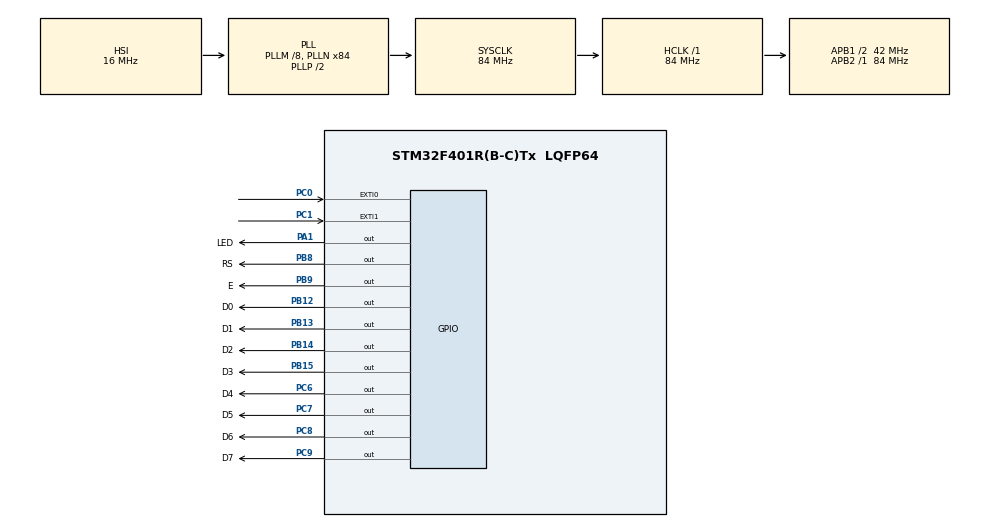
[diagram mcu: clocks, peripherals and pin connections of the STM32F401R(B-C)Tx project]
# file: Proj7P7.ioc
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Mcu.Family=STM32F4
RCC.CortexFreq_Value=84000000
PB9.GPIO_Label=E
PC9.GPIO_Label=D7
PB14.GPIO_Label=D2
PC8.Signal=GPIO_Output
PC6.Signal=GPIO_Output
PC6.GPIO_Label=D4
PC0.Signal=GPXTI0
RCC.APB1CLKDivider=RCC_HCLK_DIV2
PB13.GPIO_Label=D1
PB13.Signal=GPIO_Output
PB15.Signal=GPIO_Output
RCC.SYSCLKSource=RCC_SYSCLKSOURCE_PLLCLK
ProjectManager.StackSize=0x400
PC8.GPIO_Label=D6
PB8.GPIO_Label=RS
NVIC.EXTI1_IRQn=true\:0\:0\:false\:false\:true\:true\:true
TIM1.Prescaler=0
ProjectManager.TargetToolchain=STM32CubeIDE
RCC.HCLKFreq_Value=84000000
RCC.APB2TimFreq_Value=84000000
PC7.Signal=GPIO_Output
RCC.LSE_VALUE=32768
PA1.Signal=GPIO_Output
RCC.AHBFreq_Value=84000000
PB14.Signal=GPIO_Output
RCC.HSE_VALUE=25000000
board=custom
RCC.VCOOutputFreq_Value=168000000
PB12.GPIO_Label=D0
TIM1.TIM_MasterOutputTrigger=TIM_TRGO_UPDATE
RCC.APB2Freq_Value=84000000
PB15.GPIO_Label=D3
PA1.GPIO_Label=LED
Mcu.Name=STM32F401R(B-C)Tx
VP_TIM1_VS_ClockSourceINT.Mode=Internal
PC7.GPIO_Label=D5
RCC.48MHZClocksFreq_Value=42000000
NVIC.EXTI0_IRQn=true\:0\:0\:true\:false\:true\:true\:true
RCC.SYSCLKFreq_VALUE=84000000
Mcu.Package=LQFP64
PB9.Signal=GPIO_Output
ProjectManager.HeapSize=0x200
NVIC.TIM1_UP_TIM10_IRQn=true\:0\:0\:false\:false\:true\:true\:true
RCC.HSI_VALUE=16000000
NVIC.PriorityGroup=NVIC_PRIORITYGROUP_4
RCC.PLLM=8
RCC.PLLN=84
PC1.GPIO_ModeDefaultEXTI=GPIO_MODE_IT_FALLING
RCC.APB1TimFreq_Value=84000000
PB8.Signal=GPIO_Output
TIM1.Period=65535
PC9.Signal=GPIO_Output
RCC.APB1Freq_Value=42000000
PC1.Signal=GPXTI1
PB12.Signal=GPIO_Output

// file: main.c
/* USER CODE BEGIN Header */
/**
  ******************************************************************************
  * @file           : main.c
  * @brief          : Main program body
  ******************************************************************************
  * @attention
  *
  * <h2><center>&copy; Copyright (c) 2021 STMicroelectronics.
  * All rights reserved.</center></h2>
  *
  * This software component is licensed by ST under BSD 3-Clause license,
  * the "License"; You may not use this file except in compliance with the
  * License. You may obtain a copy of the License at:
  *                        opensource.org/licenses/BSD-3-Clause
  *
  ******************************************************************************
  */
/* USER CODE END Header */
#include "main.h"

/* USER CODE BEGIN Includes */
#include "STM_MY_LCD16X2.h"
/* USER CODE END Includes */

TIM_HandleTypeDef htim1;

/* USER CODE BEGIN PV */
uint32_t CaptureNumber=0;
uint32_t TimeCntValue=0;
uint32_t Capture=0;
/* USER CODE END PV */

void SystemClock_Config(void);
static void MX_GPIO_Init(void);
static void MX_TIM1_Init(void);

int main(void)
{

  /* MCU Configuration--------------------------------------------------------*/

  /* Reset of all peripherals, Initializes the Flash interface and the Systick. */
  HAL_Init();

  /* Configure the system clock */
  SystemClock_Config();

  /* Initialize all configured peripherals */
  MX_GPIO_Init();
  MX_TIM1_Init();

  /* Infinite loop */
  while (1)
  {
	  LCD1602_Begin8BIT(RS_GPIO_Port, RS_Pin, E_Pin, D0_GPIO_Port, D0_Pin, D1_Pin, D2_Pin, D3_Pin, D4_GPIO_Port, D4_Pin, D5_Pin, D6_Pin, D7_Pin);
	  	  	  	  int Ttime=TimeCntValue*1.0/724*2900/2;
	 			  LCD1602_PrintInt(Ttime); //shows travel time in microseconds
	 			  LCD1602_2ndLine();
	 			  float Dis=(Ttime+2.154)/29.04;
	 			 LCD1602_PrintFloat(Dis, 2);
  }
}

void SystemClock_Config(void)
{
  RCC_OscInitTypeDef RCC_OscInitStruct = {0};
  RCC_ClkInitTypeDef RCC_ClkInitStruct = {0};

  /** Configure the main internal regulator output voltage
  */
  __HAL_RCC_PWR_CLK_ENABLE();
  __HAL_PWR_VOLTAGESCALING_CONFIG(PWR_REGULATOR_VOLTAGE_SCALE2);
  /** Initializes the RCC Oscillators according to the specified parameters
  * in the RCC_OscInitTypeDef structure.
  */
  RCC_OscInitStruct.OscillatorType = RCC_OSCILLATORTYPE_HSI;
  RCC_OscInitStruct.HSIState = RCC_HSI_ON;
  RCC_OscInitStruct.HSICalibrationValue = RCC_HSICALIBRATION_DEFAULT;
  RCC_OscInitStruct.PLL.PLLState = RCC_PLL_ON;
  RCC_OscInitStruct.PLL.PLLSource = RCC_PLLSOURCE_HSI;
  RCC_OscInitStruct.PLL.PLLM = 8;
  RCC_OscInitStruct.PLL.PLLN = 84;
  RCC_OscInitStruct.PLL.PLLP = RCC_PLLP_DIV2;
  RCC_OscInitStruct.PLL.PLLQ = 4;
  if (HAL_RCC_OscConfig(&RCC_OscInitStruct) != HAL_OK)
  {
    Error_Handler();
  }
  /** Initializes the CPU, AHB and APB buses clocks
  */
  RCC_ClkInitStruct.ClockType = RCC_CLOCKTYPE_HCLK|RCC_CLOCKTYPE_SYSCLK
                              |RCC_CLOCKTYPE_PCLK1|RCC_CLOCKTYPE_PCLK2;
  RCC_ClkInitStruct.SYSCLKSource = RCC_SYSCLKSOURCE_PLLCLK;
  RCC_ClkInitStruct.AHBCLKDivider = RCC_SYSCLK_DIV1;
  RCC_ClkInitStruct.APB1CLKDivider = RCC_HCLK_DIV2;
  RCC_ClkInitStruct.APB2CLKDivider = RCC_HCLK_DIV1;

  if (HAL_RCC_ClockConfig(&RCC_ClkInitStruct, FLASH_LATENCY_2) != HAL_OK)
  {
    Error_Handler();
  }
}

static void MX_TIM1_Init(void)
{

  TIM_ClockConfigTypeDef sClockSourceConfig = {0};
  TIM_MasterConfigTypeDef sMasterConfig = {0};

  htim1.Instance = TIM1;
  htim1.Init.Prescaler = 41;
  htim1.Init.CounterMode = TIM_COUNTERMODE_UP;
  htim1.Init.Period = 65535;
  htim1.Init.ClockDivision = TIM_CLOCKDIVISION_DIV1;
  htim1.Init.RepetitionCounter = 0;
  htim1.Init.AutoReloadPreload = TIM_AUTORELOAD_PRELOAD_DISABLE;
  if (HAL_TIM_Base_Init(&htim1) != HAL_OK)
  {
    Error_Handler();
  }
  sClockSourceConfig.ClockSource = TIM_CLOCKSOURCE_INTERNAL;
  if (HAL_TIM_ConfigClockSource(&htim1, &sClockSourceConfig) != HAL_OK)
  {
    Error_Handler();
  }
  sMasterConfig.MasterOutputTrigger = TIM_TRGO_UPDATE;
  sMasterConfig.MasterSlaveMode = TIM_MASTERSLAVEMODE_DISABLE;
  if (HAL_TIMEx_MasterConfigSynchronization(&htim1, &sMasterConfig) != HAL_OK)
  {
    Error_Handler();
  }

}

static void MX_GPIO_Init(void)
{
  GPIO_InitTypeDef GPIO_InitStruct = {0};

  /* GPIO Ports Clock Enable */
  __HAL_RCC_GPIOC_CLK_ENABLE();
  __HAL_RCC_GPIOA_CLK_ENABLE();
  __HAL_RCC_GPIOB_CLK_ENABLE();

  /*Configure GPIO pin Output Level */
  HAL_GPIO_WritePin(LED_GPIO_Port, LED_Pin, GPIO_PIN_RESET);

  /*Configure GPIO pin Output Level */
  HAL_GPIO_WritePin(GPIOB, D0_Pin|D1_Pin|D2_Pin|D3_Pin
                          |RS_Pin|E_Pin, GPIO_PIN_RESET);

  /*Configure GPIO pin Output Level */
  HAL_GPIO_WritePin(GPIOC, D4_Pin|D5_Pin|D6_Pin|D7_Pin, GPIO_PIN_RESET);

  /*Configure GPIO pin : PC0 */
  GPIO_InitStruct.Pin = GPIO_PIN_0;
  GPIO_InitStruct.Mode = GPIO_MODE_IT_RISING;
  GPIO_InitStruct.Pull = GPIO_NOPULL;
  HAL_GPIO_Init(GPIOC, &GPIO_InitStruct);

  /*Configure GPIO pin : PC1 */
  GPIO_InitStruct.Pin = GPIO_PIN_1;
  GPIO_InitStruct.Mode = GPIO_MODE_IT_FALLING;
  GPIO_InitStruct.Pull = GPIO_NOPULL;
  HAL_GPIO_Init(GPIOC, &GPIO_InitStruct);

  /*Configure GPIO pin : LED_Pin */
  GPIO_InitStruct.Pin = LED_Pin;
  GPIO_InitStruct.Mode = GPIO_MODE_OUTPUT_PP;
  GPIO_InitStruct.Pull = GPIO_NOPULL;
  GPIO_InitStruct.Speed = GPIO_SPEED_FREQ_LOW;
  HAL_GPIO_Init(LED_GPIO_Port, &GPIO_InitStruct);

  /*Configure GPIO pins : D0_Pin D1_Pin D2_Pin D3_Pin
                           RS_Pin E_Pin */
  GPIO_InitStruct.Pin = D0_Pin|D1_Pin|D2_Pin|D3_Pin
                          |RS_Pin|E_Pin;
  GPIO_InitStruct.Mode = GPIO_MODE_OUTPUT_PP;
  GPIO_InitStruct.Pull = GPIO_NOPULL;
  GPIO_InitStruct.Speed = GPIO_SPEED_FREQ_LOW;
  HAL_GPIO_Init(GPIOB, &GPIO_InitStruct);

  /*Configure GPIO pins : D4_Pin D5_Pin D6_Pin D7_Pin */
  GPIO_InitStruct.Pin = D4_Pin|D5_Pin|D6_Pin|D7_Pin;
  GPIO_InitStruct.Mode = GPIO_MODE_OUTPUT_PP;
  GPIO_InitStruct.Pull = GPIO_NOPULL;
  GPIO_InitStruct.Speed = GPIO_SPEED_FREQ_LOW;
  HAL_GPIO_Init(GPIOC, &GPIO_InitStruct);

  /* EXTI interrupt init*/
  HAL_NVIC_SetPriority(EXTI0_IRQn, 0, 0);
  HAL_NVIC_EnableIRQ(EXTI0_IRQn);

  HAL_NVIC_SetPriority(EXTI1_IRQn, 0, 0);
  HAL_NVIC_EnableIRQ(EXTI1_IRQn);

}

void Error_Handler(void)
{
  __disable_irq();
  while (1)
  {
  }
}

/************************ (C) COPYRIGHT STMicroelectronics *****END OF FILE****/
